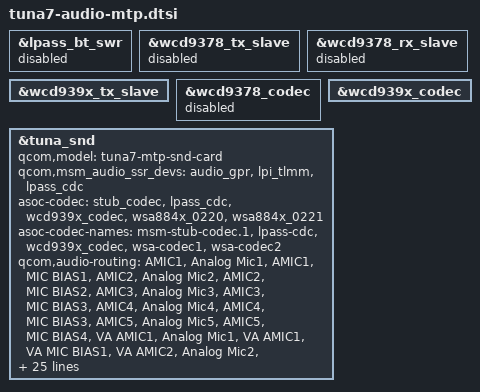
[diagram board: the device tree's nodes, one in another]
// SPDX-License-Identifier: BSD-3-Clause
/*
 * Copyright (c) 2024 Qualcomm Innovation Center, Inc. All rights reserved.
 */

#include "tuna-audio-mtp.dtsi"

&lpass_bt_swr {
	status = "disabled";
};

&wcd9378_tx_slave {
	status = "disabled";
};

&wcd9378_rx_slave {
	status = "disabled";
};

&wcd939x_tx_slave {
	status = "okay";
};

&wcd9378_codec {
	status = "disabled";
};

&wcd939x_codec {
	status = "okay";
};

&tuna_snd {
	qcom,model = "tuna7-mtp-snd-card";
	qcom,msm_audio_ssr_devs = <&audio_gpr>, <&lpi_tlmm>,
				<&lpass_cdc>;
	asoc-codec  = <&stub_codec>, <&lpass_cdc>,
			<&wcd939x_codec>, <&wsa884x_0220>,
			<&wsa884x_0221>;
	asoc-codec-names = "msm-stub-codec.1", "lpass-cdc",
				"wcd939x_codec", "wsa-codec1",
				"wsa-codec2";

	qcom,audio-routing =
			"AMIC1", "Analog Mic1",
			"AMIC1", "MIC BIAS1",
			"AMIC2", "Analog Mic2",
			"AMIC2", "MIC BIAS2",
			"AMIC3", "Analog Mic3",
			"AMIC3", "MIC BIAS3",
			"AMIC4", "Analog Mic4",
			"AMIC4", "MIC BIAS3",
			"AMIC5", "Analog Mic5",
			"AMIC5", "MIC BIAS4",
			"VA AMIC1", "Analog Mic1",
			"VA AMIC1", "VA MIC BIAS1",
			"VA AMIC2", "Analog Mic2",
			"VA AMIC2", "VA MIC BIAS2",
			"VA AMIC3", "Analog Mic3",
			"VA AMIC3", "VA MIC BIAS3",
			"VA AMIC4", "Analog Mic4",
			"VA AMIC4", "VA MIC BIAS3",
			"VA AMIC5", "Analog Mic5",
			"VA AMIC5", "VA MIC BIAS4",
			"TX DMIC0", "Digital Mic0",
			"TX DMIC0", "MIC BIAS3",
			"TX DMIC1", "Digital Mic1",
			"TX DMIC1", "MIC BIAS3",
			"TX DMIC2", "Digital Mic2",
			"TX DMIC2", "MIC BIAS1",
			"TX DMIC3", "Digital Mic3",
			"TX DMIC3", "MIC BIAS1",
			"IN1_HPHL", "HPHL_OUT",
			"IN2_HPHR", "HPHR_OUT",
			"IN3_AUX", "AUX_OUT",
			"WSA SRC0_INP", "SRC0",
			"WSA_TX DEC0_INP", "TX DEC0 MUX",
			"WSA_TX DEC1_INP", "TX DEC1 MUX",
			"RX_TX DEC0_INP", "TX DEC0 MUX",
			"RX_TX DEC1_INP", "TX DEC1 MUX",
			"RX_TX DEC2_INP", "TX DEC2 MUX",
			"RX_TX DEC3_INP", "TX DEC3 MUX",
			"SpkrLeft IN", "WSA_SPK1 OUT",
			"SpkrRight IN", "WSA_SPK2 OUT",
			"VA SWR_INPUT", "VA_SWR_CLK",
			"VA_AIF1 CAP", "VA_SWR_CLK",
			"VA_AIF2 CAP", "VA_SWR_CLK",
			"VA_AIF3 CAP", "VA_SWR_CLK",
			"VA DMIC0", "Digital Mic0",
			"VA DMIC1", "Digital Mic1",
			"VA DMIC2", "Digital Mic2",
			"VA DMIC3", "Digital Mic3",
			"VA DMIC0", "VA MIC BIAS3",
			"VA DMIC1", "VA MIC BIAS3",
			"VA DMIC2", "VA MIC BIAS1",
			"VA DMIC3", "VA MIC BIAS1";
};
